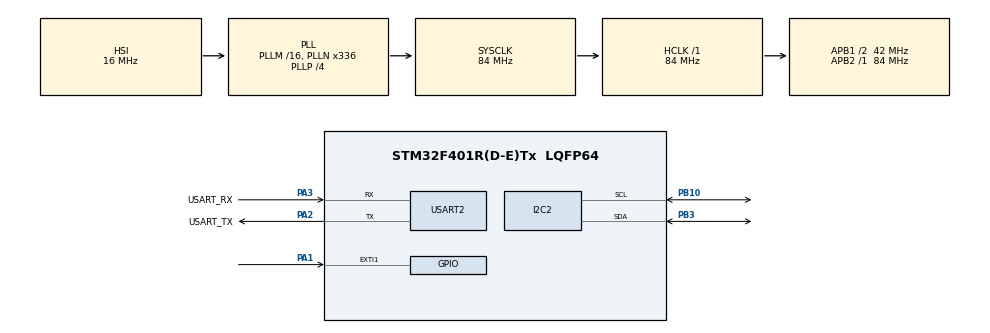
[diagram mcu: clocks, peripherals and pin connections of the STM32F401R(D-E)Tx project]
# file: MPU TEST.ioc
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I2C2.I2C_Mode=I2C_Fast
Mcu.Family=STM32F4
Mcu.Name=STM32F401R(D-E)Tx
Mcu.Package=LQFP64
NVIC.I2C2_EV_IRQn=true\:0\:0\:false\:false\:true\:true\:true
NVIC.PriorityGroup=NVIC_PRIORITYGROUP_0
NVIC.USART2_IRQn=true\:0\:0\:false\:false\:true\:true\:true
PA1.Signal=GPXTI1
PA2.GPIO_Label=USART_TX
PA2.GPIO_Mode=GPIO_MODE_AF_PP
PA2.GPIO_PuPd=GPIO_NOPULL
PA2.GPIO_Speed=GPIO_SPEED_FREQ_LOW
PA2.Mode=Asynchronous
PA2.Signal=USART2_TX
PA3.GPIO_Label=USART_RX
PA3.GPIO_Mode=GPIO_MODE_AF_PP
PA3.GPIO_PuPd=GPIO_NOPULL
PA3.GPIO_Speed=GPIO_SPEED_FREQ_LOW
PA3.Mode=Asynchronous
PA3.Signal=USART2_RX
PB10.Mode=I2C
PB10.Signal=I2C2_SCL
PB3.Mode=I2C
PB3.Signal=I2C2_SDA
PH0\ -\ OSC_IN.Mode=HSE-External-Oscillator
PH0\ -\ OSC_IN.Signal=RCC_OSC_IN
PH1\ -\ OSC_OUT.Mode=HSE-External-Oscillator
PH1\ -\ OSC_OUT.Signal=RCC_OSC_OUT
ProjectManager.HeapSize=0x200
ProjectManager.StackSize=0x400
ProjectManager.TargetToolchain=MDK-ARM V5
RCC.AHBFreq_Value=84000000
RCC.APB1CLKDivider=RCC_HCLK_DIV2
RCC.APB1Freq_Value=42000000
RCC.APB1TimFreq_Value=84000000
RCC.APB2Freq_Value=84000000
RCC.APB2TimFreq_Value=84000000
RCC.CortexFreq_Value=84000000
RCC.HCLKFreq_Value=84000000
RCC.HSE_VALUE=8000000
RCC.HSI_VALUE=16000000
RCC.LSE_VALUE=32768
RCC.PLLN=336
RCC.PLLP=RCC_PLLP_DIV4
RCC.PLLQ=7
RCC.SYSCLKFreq_VALUE=84000000
RCC.SYSCLKSource=RCC_SYSCLKSOURCE_PLLCLK
RCC.VCOOutputFreq_Value=336000000
USART2.VirtualMode=VM_ASYNC
board=NUCLEO-F401RE

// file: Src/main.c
/* USER CODE BEGIN Header */
/**
  ******************************************************************************
  * @file           : main.c
  * @brief          : Main program body
  ******************************************************************************
  ** This notice applies to any and all portions of this file
  * that are not between comment pairs USER CODE BEGIN and
  * USER CODE END. Other portions of this file, whether
  * inserted by the user or by software development tools
  * are owned by their respective copyright owners.
  *
  * COPYRIGHT(c) 2019 STMicroelectronics
  *
  * Redistribution and use in source and binary forms, with or without modification,
  * are permitted provided that the following conditions are met:
  *   1. Redistributions of source code must retain the above copyright notice,
  *      this list of conditions and the following disclaimer.
  *   2. Redistributions in binary form must reproduce the above copyright notice,
  *      this list of conditions and the following disclaimer in the documentation
  *      and/or other materials provided with the distribution.
  *   3. Neither the name of STMicroelectronics nor the names of its contributors
  *      may be used to endorse or promote products derived from this software
  *      without specific prior written permission.
  *
  * THIS SOFTWARE IS PROVIDED BY THE COPYRIGHT HOLDERS AND CONTRIBUTORS "AS IS"
  * AND ANY EXPRESS OR IMPLIED WARRANTIES, INCLUDING, BUT NOT LIMITED TO, THE
  * IMPLIED WARRANTIES OF MERCHANTABILITY AND FITNESS FOR A PARTICULAR PURPOSE ARE
  * DISCLAIMED. IN NO EVENT SHALL THE COPYRIGHT HOLDER OR CONTRIBUTORS BE LIABLE
  * FOR ANY DIRECT, INDIRECT, INCIDENTAL, SPECIAL, EXEMPLARY, OR CONSEQUENTIAL
  * DAMAGES (INCLUDING, BUT NOT LIMITED TO, PROCUREMENT OF SUBSTITUTE GOODS OR
  * SERVICES; LOSS OF USE, DATA, OR PROFITS; OR BUSINESS INTERRUPTION) HOWEVER
  * CAUSED AND ON ANY THEORY OF LIABILITY, WHETHER IN CONTRACT, STRICT LIABILITY,
  * OR TORT (INCLUDING NEGLIGENCE OR OTHERWISE) ARISING IN ANY WAY OUT OF THE USE
  * OF THIS SOFTWARE, EVEN IF ADVISED OF THE POSSIBILITY OF SUCH DAMAGE.
  *
  ******************************************************************************
  */
/* USER CODE END Header */

#include "main.h"
#include "i2c.h"
#include "usart.h"
#include "gpio.h"

/* USER CODE BEGIN Includes */

#include "stm32f4xx.h"
#include "stdio.h"
#include "arch.h"

/* USER CODE END Includes */

void SystemClock_Config(void);
/* USER CODE BEGIN PFP */

#ifdef __GNUC__
#define PUTCHAR_PROTOTYPE int __io_putchar(int ch)
#else
#define PUTCHAR_PROTOTYPE int fputc(int ch, FILE *f)
#endif

/* USER CODE END PFP */

/* USER CODE BEGIN 0 */

PUTCHAR_PROTOTYPE
{
    HAL_UART_Transmit(&huart2, (uint8_t *)&ch, 1, 0xffff);
    return ch;
}

/* USER CODE END 0 */

int main(void)
{

  /* MCU Configuration--------------------------------------------------------*/

  /* Reset of all peripherals, Initializes the Flash interface and the Systick. */
  HAL_Init();

  /* Configure the system clock */
  SystemClock_Config();

  /* Initialize all configured peripherals */
  MX_GPIO_Init();
  MX_USART2_UART_Init();
  MX_I2C2_Init();
  /* USER CODE BEGIN 2 */
	arch();
  /* USER CODE END 2 */

  /* Infinite loop */
  while (1)
  {

  }
}

void SystemClock_Config(void)
{
  RCC_OscInitTypeDef RCC_OscInitStruct = {0};
  RCC_ClkInitTypeDef RCC_ClkInitStruct = {0};

  /** Configure the main internal regulator output voltage
  */
  __HAL_RCC_PWR_CLK_ENABLE();
  __HAL_PWR_VOLTAGESCALING_CONFIG(PWR_REGULATOR_VOLTAGE_SCALE2);
  /** Initializes the CPU, AHB and APB busses clocks
  */
  RCC_OscInitStruct.OscillatorType = RCC_OSCILLATORTYPE_HSI;
  RCC_OscInitStruct.HSIState = RCC_HSI_ON;
  RCC_OscInitStruct.HSICalibrationValue = RCC_HSICALIBRATION_DEFAULT;
  RCC_OscInitStruct.PLL.PLLState = RCC_PLL_ON;
  RCC_OscInitStruct.PLL.PLLSource = RCC_PLLSOURCE_HSI;
  RCC_OscInitStruct.PLL.PLLM = 16;
  RCC_OscInitStruct.PLL.PLLN = 336;
  RCC_OscInitStruct.PLL.PLLP = RCC_PLLP_DIV4;
  RCC_OscInitStruct.PLL.PLLQ = 7;
  if (HAL_RCC_OscConfig(&RCC_OscInitStruct) != HAL_OK)
  {
    Error_Handler();
  }
  /** Initializes the CPU, AHB and APB busses clocks
  */
  RCC_ClkInitStruct.ClockType = RCC_CLOCKTYPE_HCLK|RCC_CLOCKTYPE_SYSCLK
                              |RCC_CLOCKTYPE_PCLK1|RCC_CLOCKTYPE_PCLK2;
  RCC_ClkInitStruct.SYSCLKSource = RCC_SYSCLKSOURCE_PLLCLK;
  RCC_ClkInitStruct.AHBCLKDivider = RCC_SYSCLK_DIV1;
  RCC_ClkInitStruct.APB1CLKDivider = RCC_HCLK_DIV2;
  RCC_ClkInitStruct.APB2CLKDivider = RCC_HCLK_DIV1;

  if (HAL_RCC_ClockConfig(&RCC_ClkInitStruct, FLASH_LATENCY_2) != HAL_OK)
  {
    Error_Handler();
  }
}

void Error_Handler(void)
{
}

/************************ (C) COPYRIGHT STMicroelectronics *****END OF FILE****/
